# STM32F303R8T7 register map
File version: 1.0
Registers are 32-bit, access not given, reset 0x0 unless marked. A register's access mark holds for its fields unless they carry their own. Offsets are from the block's base; [hi:lo] are bit positions; {n}, {i} and the like mark numbered series; 'fields as' and 'values as' point back to an identical list.

## DAC1
Base 0x40007400
Same registers: DAC2 0x40009800
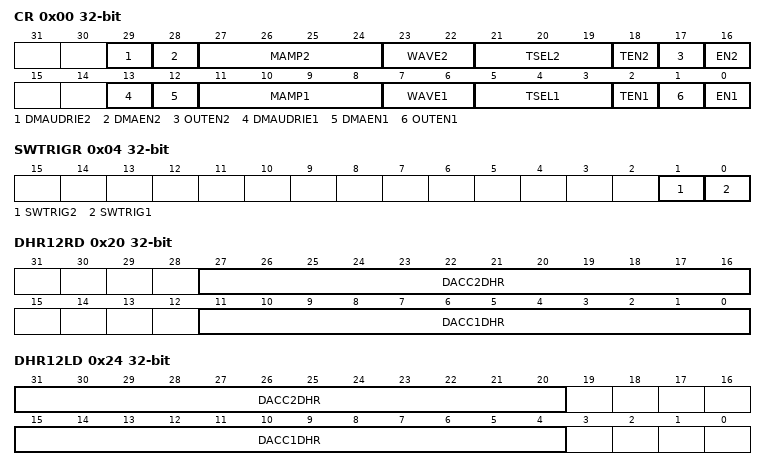
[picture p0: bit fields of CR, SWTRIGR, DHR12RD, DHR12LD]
0x00 CR
  [29] DMAUDRIE2, [28] DMAEN2, [27:24] MAMP2, [23:22] WAVE2, [21:19] TSEL2, [18] TEN2, [17] OUTEN2, [16] EN2, [13] DMAUDRIE1, [12] DMAEN1, [11:8] MAMP1, [7:6] WAVE1, [5:3] TSEL1, [2] TEN1, [1] OUTEN1, [0] EN1
0x04 SWTRIGR
  [1] SWTRIG2, [0] SWTRIG1
0x08 DHR12R1
  [11:0] DACC1DHR
0x0C DHR12L1
  [15:4] DACC1DHR
0x10 DHR8R1
  [7:0] DACC1DHR
0x14 DHR12R2
  [11:0] DACC2DHR
0x18 DHR12L2
  [15:4] DACC2DHR
0x1C DHR8R2
  [7:0] DACC2DHR
0x20 DHR12RD
  [27:16] DACC2DHR, [11:0] DACC1DHR
0x24 DHR12LD
  [31:20] DACC2DHR, [15:4] DACC1DHR
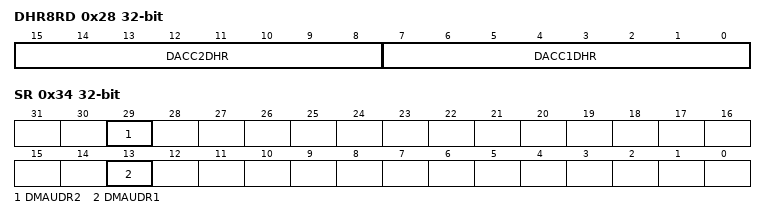
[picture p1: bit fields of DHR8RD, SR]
0x28 DHR8RD
  [15:8] DACC2DHR, [7:0] DACC1DHR
0x2C DOR1
  [11:0] DACC1DOR
0x30 DOR2
  [11:0] DACC2DOR
0x34 SR
  [29] DMAUDR2, [13] DMAUDR1

## SYSCFG
Base 0x40010000
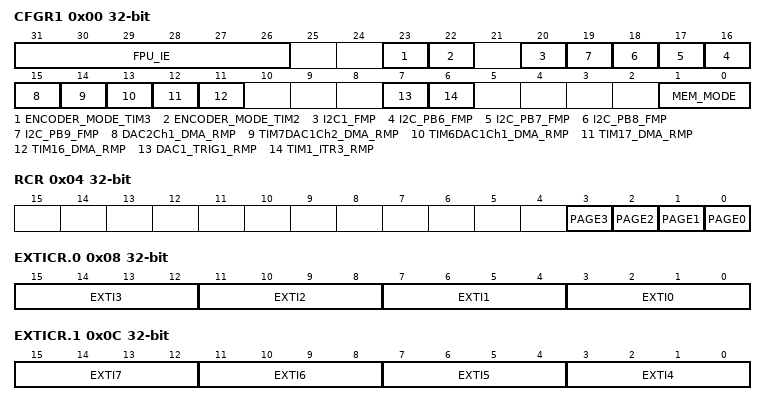
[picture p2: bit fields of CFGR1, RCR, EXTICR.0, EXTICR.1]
0x00 CFGR1
  [31:26] FPU_IE, [23] ENCODER_MODE_TIM3, [22] ENCODER_MODE_TIM2, [20] I2C1_FMP, [n+10] I2C_PB{n}_FMP (n=6..9), [15] DAC2Ch1_DMA_RMP, [14] TIM7DAC1Ch2_DMA_RMP, [13] TIM6DAC1Ch1_DMA_RMP, [12] TIM17_DMA_RMP, [11] TIM16_DMA_RMP, [7] DAC1_TRIG1_RMP, [6] TIM1_ITR3_RMP, [1:0] MEM_MODE
0x04 RCR
  [n] PAGE{n} (n=0..3)
0x08 EXTICR.0
  [4n+3:4n] EXTI{n} (n=0..3)
0x0C EXTICR.1
  [4n-13:4n-16] EXTI{n} (n=4..7)
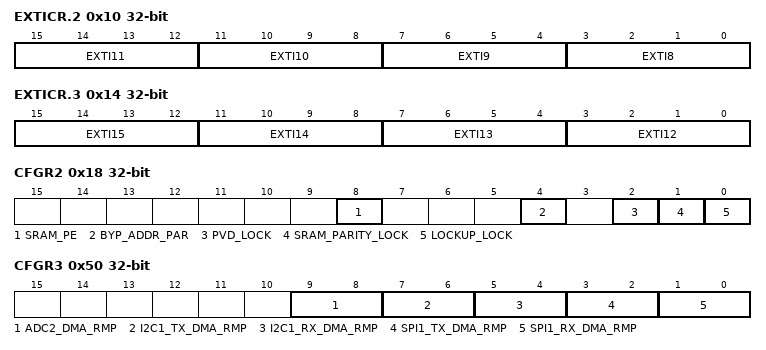
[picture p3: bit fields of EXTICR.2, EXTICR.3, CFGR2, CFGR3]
0x10 EXTICR.2
  [4n-29:4n-32] EXTI{n} (n=8..11)
0x14 EXTICR.3
  [4n-45:4n-48] EXTI{n} (n=12..15)
0x18 CFGR2
  [8] SRAM_PE, [4] BYP_ADDR_PAR, [2] PVD_LOCK, [1] SRAM_PARITY_LOCK, [0] LOCKUP_LOCK
0x50 CFGR3
  [9:8] ADC2_DMA_RMP, [7:6] I2C1_TX_DMA_RMP, [5:4] I2C1_RX_DMA_RMP, [3:2] SPI1_TX_DMA_RMP, [1:0] SPI1_RX_DMA_RMP

## COMP2
Base 0x40010020
Same registers: COMP4 0x40010028, COMP6 0x40010030
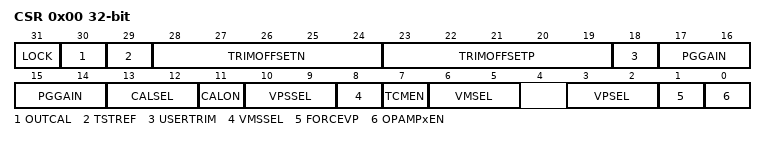
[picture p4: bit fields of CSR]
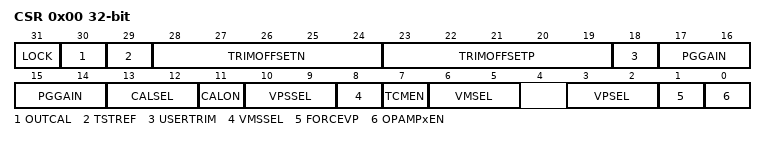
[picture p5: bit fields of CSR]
0x00 CSR
  [31] COMPxLOCK, [30] COMPxOUT, [19:18] COMPxBLANKING, [15] COMPxPOL, [13:10] COMPxOUTSEL, [22:4] COMPxINSEL, [0] COMPxEN

## COMP
Base 0x40010020
0x00 CSR
  [31] COMPxLOCK, [30] COMPxOUT, [19:18] COMPxBLANKING, [15] COMPxPOL, [13:10] COMPxOUTSEL, [22:4] COMPxINSEL, [0] COMPxEN

## OPAMP
Base 0x4001003C
0x00 CSR
  [31] LOCK, [30] OUTCAL, [29] TSTREF, [28:24] TRIMOFFSETN, [23:19] TRIMOFFSETP, [18] USERTRIM, [17:14] PGGAIN, [13:12] CALSEL, [11] CALON, [10:9] VPSSEL, [8] VMSSEL, [7] TCMEN, [6:5] VMSEL, [3:2] VPSEL, [1] FORCEVP, [0] OPAMPxEN

## OPAMP2
Base 0x4001003C
0x00 CSR
  [31] LOCK, [30] OUTCAL, [29] TSTREF, [28:24] TRIMOFFSETN, [23:19] TRIMOFFSETP, [18] USERTRIM, [17:14] PGGAIN, [13:12] CALSEL, [11] CALON, [10:9] VPSSEL, [8] VMSSEL, [7] TCMEN, [6:5] VMSEL, [3:2] VPSEL, [1] FORCEVP, [0] OPAMPxEN

## EXTI
Base 0x40010400
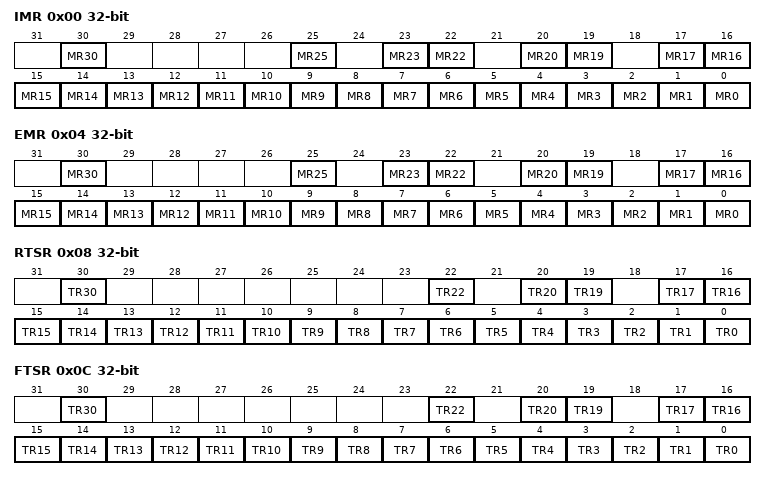
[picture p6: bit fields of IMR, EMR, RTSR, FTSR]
0x00 IMR
  [30] MR30, [25] MR25, [23] MR23, [22] MR22, [20] MR20, [19] MR19, [n] MR{n} (n=0..17)
0x04 EMR
  fields as IMR
0x08 RTSR
  [30] TR30, [22] TR22, [20] TR20, [19] TR19, [n] TR{n} (n=0..17)
0x0C FTSR
  [30] TR30, [22] TR22, [20] TR20, [19] TR19, [n] TR{n} (n=0..17)
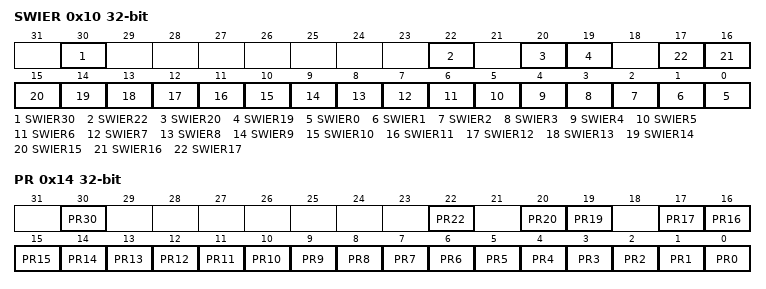
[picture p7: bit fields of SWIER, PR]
0x10 SWIER
  [30] SWIER30, [22] SWIER22, [20] SWIER20, [19] SWIER19, [n] SWIER{n} (n=0..17)
0x14 PR
  [30] PR30, [22] PR22, [20] PR20, [19] PR19, [n] PR{n} (n=0..17)
0x20 IMR2
  [0] MR32
0x24 EMR2
  [0] MR32
0x28 RTSR2
  [0] TR32
0x2C FTSR2
  [0] TR32
0x30 SWIER2
  [0] SWIER32
0x34 PR2
  [0] PR32

## SPI1
Base 0x40013000
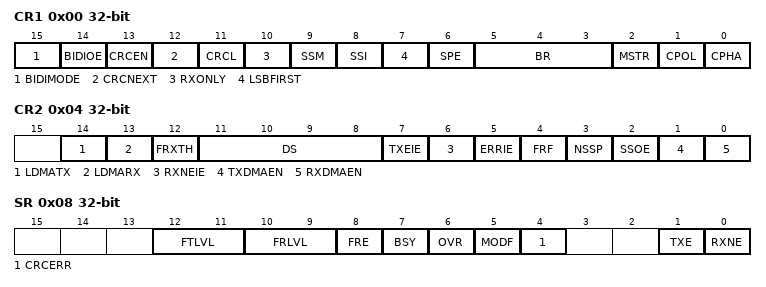
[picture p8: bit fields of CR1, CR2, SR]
0x00 CR1
  [15] BIDIMODE, [14] BIDIOE, [13] CRCEN, [12] CRCNEXT, [11] CRCL, [10] RXONLY, [9] SSM, [8] SSI, [7] LSBFIRST, [6] SPE, [5:3] BR, [2] MSTR, [1] CPOL, [0] CPHA
0x04 CR2
  [14] LDMATX, [13] LDMARX, [12] FRXTH, [11:8] DS, [7] TXEIE, [6] RXNEIE, [5] ERRIE, [4] FRF, [3] NSSP, [2] SSOE, [1] TXDMAEN, [0] RXDMAEN
0x08 SR
  [12:11] FTLVL, [10:9] FRLVL, [8] FRE, [7] BSY, [6] OVR, [5] MODF, [4] CRCERR, [1] TXE, [0] RXNE
0x0C DR
  [15:0] DR
0x10 CRCPR
  [15:0] CRCPOLY
0x14 RXCRCR
  [15:0] RXCRC
0x18 TXCRCR
  [15:0] TXCRC

## DMA1
Base 0x40020000
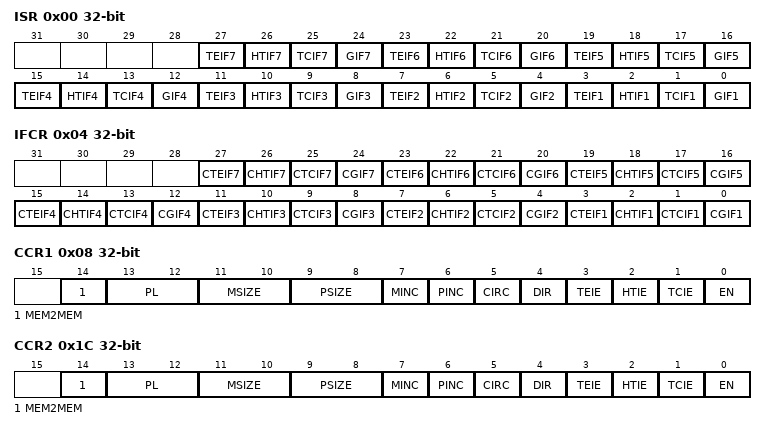
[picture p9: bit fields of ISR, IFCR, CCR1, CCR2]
0x00 ISR
  [4n-1] TEIF{n} (n=1..7), [4n-2] HTIF{n} (n=1..7), [4n-3] TCIF{n} (n=1..7), [4n-4] GIF{n} (n=1..7)
0x04 IFCR
  [4n-1] CTEIF{n} (n=1..7), [4n-2] CHTIF{n} (n=1..7), [4n-3] CTCIF{n} (n=1..7), [4n-4] CGIF{n} (n=1..7)
0x08 CCR1
  [14] MEM2MEM, [13:12] PL, [11:10] MSIZE, [9:8] PSIZE, [7] MINC, [6] PINC, [5] CIRC, [4] DIR, [3] TEIE, [2] HTIE, [1] TCIE, [0] EN
0x0C CNDTR1
  [15:0] NDT
0x10 CPAR1
  [31:0] PA
{0x0+0x14*i} CMAR{i} (i=1..7)
  [31:0] MA
0x1C CCR2
  fields as CCR1
0x20 CNDTR2
  [15:0] NDT
0x24 CPAR2
  [31:0] PA
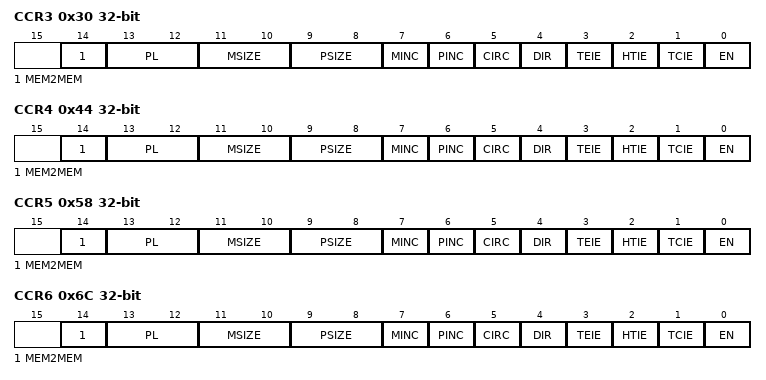
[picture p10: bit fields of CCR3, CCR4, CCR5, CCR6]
0x30 CCR3
  fields as CCR1
0x34 CNDTR3
  [15:0] NDT
0x38 CPAR3
  [31:0] PA
0x44 CCR4
  fields as CCR1
0x48 CNDTR4
  [15:0] NDT
0x4C CPAR4
  [31:0] PA
0x58 CCR5
  fields as CCR1
0x5C CNDTR5
  [15:0] NDT
0x60 CPAR5
  [31:0] PA
0x6C CCR6
  fields as CCR1
0x70 CNDTR6
  [15:0] NDT
0x74 CPAR6
  [31:0] PA
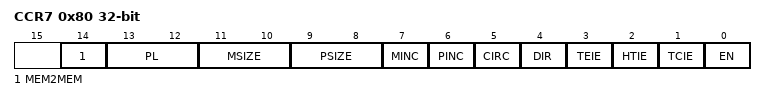
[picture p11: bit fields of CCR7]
0x80 CCR7
  fields as CCR1
0x84 CNDTR7
  [15:0] NDT
0x88 CPAR7
  [31:0] PA
